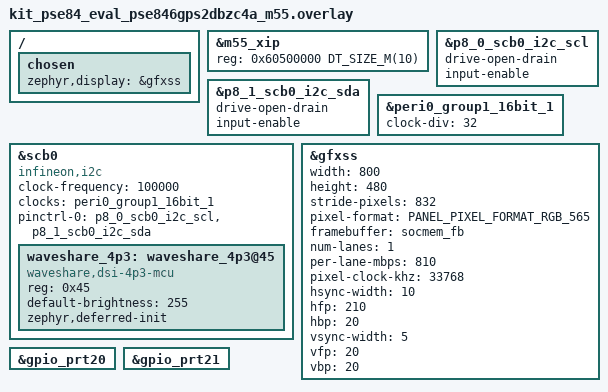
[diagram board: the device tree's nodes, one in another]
#include <zephyr/dt-bindings/display/panel.h>

/*
 * Extend the M55 XIP partition from its default 2 MB to 10 MB so there's
 * room for 8.64 MB of embedded animation frame data alongside the app
 * code. The remaining ~5 MB of free QSPI flash beyond 0x60F00000 stays
 * unallocated for future use. Safe because the M55 is loaded by
 * Cy_SysEnableCM55() directly from this region and is not mcuboot-signed,
 * so no slot-size math changes are needed in the signing pipeline.
 */
&m55_xip {
	reg = <0x60500000 DT_SIZE_M(10)>;
};

/* I2C on SCB0 — used by the Waveshare 4.3" panel MCU at 0x45 */
&p8_0_scb0_i2c_scl {
	drive-open-drain;
	input-enable;
};

&p8_1_scb0_i2c_sda {
	drive-open-drain;
	input-enable;
};

&peri0_group1_16bit_1 {
	status = "okay";
	clock-div = <32>;
};

i2c0: &scb0 {
	compatible = "infineon,i2c";
	status = "okay";
	clock-frequency = <100000>;
	#address-cells = <1>;
	#size-cells = <0>;
	clocks = <&peri0_group1_16bit_1>;
	pinctrl-0 = <&p8_0_scb0_i2c_scl &p8_1_scb0_i2c_sda>;
	pinctrl-names = "default";

	waveshare_4p3: waveshare_4p3@45 {
		compatible = "waveshare,dsi-4p3-mcu";
		reg = <0x45>;
		default-brightness = <255>;
		/* Panel MCU needs DSI link up before it responds on I2C;
		 * let the GFXSS driver trigger init via device_init() after
		 * its own Cy_GFXSS_Init and a stabilization delay.
		 */
		zephyr,deferred-init;
		status = "okay";
	};
};

/* GFXSS display controller — 800x480 Waveshare 4.3" panel.
 * Uses stride-pixels = 832 so RGB565 rows are 128-byte aligned for the
 * DC DMA; the panel's bridge chip crops the tail pixels. The framebuffer
 * lives in the board's socmem_fb SOCMEM region. */
&gfxss {
	status = "okay";
	width = <800>;
	height = <480>;
	stride-pixels = <832>;
	pixel-format = <PANEL_PIXEL_FORMAT_RGB_565>;
	framebuffer = <&socmem_fb>;
	num-lanes = <1>;
	per-lane-mbps = <810>;
	pixel-clock-khz = <33768>;
	hsync-width = <10>;
	hfp = <210>;
	hbp = <20>;
	vsync-width = <5>;
	vfp = <20>;
	vbp = <20>;
};

/ {
	chosen {
		zephyr,display = &gfxss;
	};
};

&gpio_prt20 {
	status = "okay";
};

&gpio_prt21 {
	status = "okay";
};
